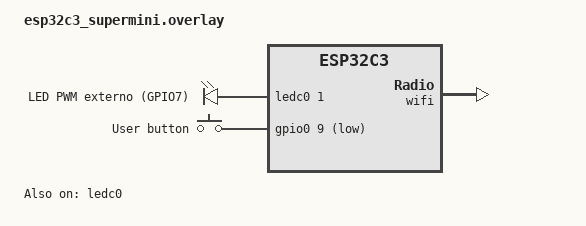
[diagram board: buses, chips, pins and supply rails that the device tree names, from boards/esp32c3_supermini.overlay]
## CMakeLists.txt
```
# SPDX-License-Identifier: Apache-2.0

cmake_minimum_required(VERSION 3.20.0)


# Adiciona o diretório camera_service como módulo extra do Zephyr
set(ZEPHYR_EXTRA_MODULES
    ${CMAKE_CURRENT_SOURCE_DIR}/camera_service
)

find_package(Zephyr REQUIRED HINTS $ENV{ZEPHYR_BASE})
project(emb_base_sample)

# Diretório de headers
zephyr_include_directories(include)

# Arquivos .c
target_sources(app PRIVATE
    src/main.c
    src/sensor_thread.c
    src/control_thread.c
    src/display_thread.c
    src/display.c
    src/radar_core.c
    src/plate_validator.c
)
```

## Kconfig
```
menu "Zephyr"
source "Kconfig.zephyr"

config DISPLAY_ANSI_COLORS
    bool "Ativar cores ANSI no display"
    default y

config DISPLAY_ANSI_CLEAR_ON_UPDATE
    bool "Limpar tela a cada atualização"
    default y

config DISPLAY_ALERT_PERCENT
    int "Percentual de alerta (em % do limite)"
    default 90

config DISPLAY_LIMITE_LEVE
    int "Limite de velocidade para veículos leves"
    default 60


config DISPLAY_LIMITE_PESADO
    int "Limite de velocidade para veículos pesados"
    default 40


config CAMERA_FAKE_FAIL_RATE
    int "Taxa de falha da câmera (%)"
    default 10

config RADAR_CAMERA_FAILURE_RATE_PERCENT
    int "Porcentagem de falha simulada da câmera (%)"
    default 10
    range 0 100

config RADAR_SPEED_LIMIT_LIGHT_KMH
  int "Limit speed for light vehicles (msec)"
  default 60
  range 0 1000

config RADAR_SPEED_LIMIT_HEAVY_KMH
  int "Limit speed for heavy vehicles (msec)"
  default 50
  range 0 1000

config RADAR_SENSOR_DISTANCE_MM
  int "Distances between radar sensors (mm)"
  default 10000
  range 0 100000

endmenu
```

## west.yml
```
# Example T2 west.yml, using manifest imports.
manifest:
  remotes:
    - name: zephyrproject-rtos
      url-base: https://github.com/zephyrproject-rtos
  projects:
    - name: zephyr
      remote: zephyrproject-rtos
      clone-depth: 1
      revision: v4.1.0
      import:
        name-allowlist:
          - cmsis # required by the ARM port
          - hal_nordic # required by the custom_plank board (Nordic based)
path: hello_world
```

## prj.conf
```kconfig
CONFIG_DISPLAY=y
CONFIG_PRINTK=y

CONFIG_TEST_RANDOM_GENERATOR=y
CONFIG_ZBUS=y
CONFIG_ZBUS_MSG_SUBSCRIBER=y
CONFIG_QEMU_ICOUNT=n

CONFIG_GPIO_EMUL=y
CONFIG_GPIO=y
CONFIG_LOG=y

CONFIG_UART_CONSOLE=y

CONFIG_RADAR_SPEED_LIMIT_LIGHT_KMH=80
CONFIG_RADAR_SPEED_LIMIT_HEAVY_KMH=60
CONFIG_RADAR_SENSOR_DISTANCE_MM=3000
```

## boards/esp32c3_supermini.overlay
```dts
#include <zephyr/dt-bindings/gpio/gpio.h>
#include <zephyr/dt-bindings/pwm/pwm.h>
#include <zephyr/dt-bindings/pinctrl/esp32-pinctrl.h>

/* ---- LED PWM em GPIO7 usando LEDC canal 1 ---- */
&pinctrl {
    /* Verifique se este macro existe para o C3: LEDC_CH1_GPIO7 */
    ledc0_gpio7_ch1: ledc0_gpio7_ch1 {
        group1 {
            pinmux = <LEDC_CH1_GPIO7>;
            output-enable;
        };
    };
};

&wifi {
    status = "okay";
};


&ledc0 {
    status = "okay";
    pinctrl-0 = <&ledc0_gpio7_ch1>;
    pinctrl-names = "default";

    #address-cells = <1>;
    #size-cells = <0>;

    channel1: channel@1 {
        reg = <1>;     /* Canal 1 */
        timer = <0>;   /* Timer 0 (0..3) */
        /* inverted;  // opcional */
    };
};

 /{
    aliases {
        led0 = &pwm_led0;
        sw0  = &button0;
    };

    pwmleds {
        compatible = "pwm-leds";
        pwm_led0: pwm_led_0 {
            /* controller, canal, período(ns), flags */
            pwms = <&ledc0 1 1000000 PWM_POLARITY_NORMAL>; /* 1 kHz */
            label = "LED PWM externo (GPIO7)";
        };
    };

    gpio_keys {
        compatible = "gpio-keys";
        button0: button_0 {
            label = "User button";
            gpios = <&gpio0 9 (GPIO_PULL_UP | GPIO_ACTIVE_LOW)>;
        };
    };
};
```

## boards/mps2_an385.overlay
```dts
#include <zephyr/dt-bindings/gpio/gpio.h>

/ {
    chosen {
        zephyr,display = &dummy_dc;
    };

    dummy_dc: dummy_dc {
        compatible = "zephyr,dummy-dc";
        status = "okay";
        width = <80>;
        height = <24>;
    };
};

	aliases {
		button0 = &button0;
		button1 = &button1;
	};

	gpio_sim: gpio_sim {
		compatible = "zephyr,gpio-emul";
		status = "okay";
		gpio-controller;
		#gpio-cells = <2>;
		ngpios = <32>;

		rising-edge;
		falling-edge;
		high-level;
		low-level;
	};

	gpio_keys {
		compatible = "gpio-keys";
		debounce-interval-ms = <20>;

		button0: button_0 {
			gpios = <&gpio_sim 5 (GPIO_PULL_UP | GPIO_ACTIVE_LOW)>;
		};

		button1: button_1 {
			gpios = <&gpio_sim 6 (GPIO_PULL_UP | GPIO_ACTIVE_LOW)>;
		};
	};
};
```

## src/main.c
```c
#include "zephyr/toolchain.h"
#include <stdbool.h>
#include <stdint.h>
#include <zephyr/device.h>
#include <zephyr/drivers/gpio.h>
#include <zephyr/drivers/gpio/gpio_emul.h>
#include <zephyr/drivers/pwm.h>
#include <zephyr/drivers/uart.h>
#include <zephyr/kernel.h>
#include <zephyr/logging/log.h>
#include <zephyr/sys/printk.h>
#include <zephyr/zbus/zbus.h>
#include "camera_service.h"
#include "display.h"
#include "radar_types.h"


LOG_MODULE_REGISTER(semaforo);

K_MSGQ_DEFINE(display_queue, sizeof(struct display_msg), 10, 4);
K_MSGQ_DEFINE(sensor_queue, sizeof(struct data), 10, 4);
K_MSGQ_DEFINE(vehicle_queue, sizeof(struct data), 10, 4);

ZBUS_MSG_SUBSCRIBER_DEFINE(msub_camera_evt);
ZBUS_CHAN_ADD_OBS(chan_camera_evt, msub_camera_evt, 3);

static const struct device *const console_dev = DEVICE_DT_GET(DT_CHOSEN(zephyr_console));
static const struct gpio_dt_spec sensor0 = GPIO_DT_SPEC_GET(DT_ALIAS(button0), gpios);
static const struct gpio_dt_spec sensor1 = GPIO_DT_SPEC_GET(DT_ALIAS(button1), gpios);

extern void sensor_thread(void *, void *, void *);
extern void control_thread(void *, void *, void *);
extern void display_thread(void *, void *, void *);

K_THREAD_DEFINE(control_thread_id, 1024, control_thread, NULL, NULL, NULL, 4, 0, 0);
K_THREAD_DEFINE(sensor_thread_id, 1024, sensor_thread, NULL, NULL, NULL, 4, 0, 0);
K_THREAD_DEFINE(display_thread_id, 1024, display_thread, NULL, NULL, NULL, 4, 0, 0);

static struct gpio_callback sensor0_data;
static struct gpio_callback sensor1_data;



static void sensor0_cb(const struct device *dev, struct gpio_callback *cb, uint32_t pins)
{
	struct data data;

	data.item.from = SENSOR_0;
	data.value.timestamp = k_uptime_get_32();

	k_msgq_put(&sensor_queue, &data, K_NO_WAIT);
}

static void sensor1_cb(const struct device *dev, struct gpio_callback *cb, uint32_t pins)
{
	struct data data;

	data.item.from = SENSOR_1;
	data.value.timestamp = k_uptime_get_32();

	k_msgq_put(&sensor_queue, &data, K_NO_WAIT);
}


int main(void)
{
	int ret;
	uint8_t c;

	LOG_INF("Starting system...");

	if (!gpio_is_ready_dt(&sensor0) || !gpio_is_ready_dt(&sensor1)) {
		LOG_ERR("Error: Sensor GPIO devices are not ready\n");
		return 0;
	}

	ret = gpio_pin_configure_dt(&sensor0, GPIO_INPUT);
	if (ret < 0) {
		LOG_ERR("Error: Failed to configure Sensor 0 pin (err: %d)\n", ret);
		return 0;
	}

	ret = gpio_pin_configure_dt(&sensor1, GPIO_INPUT);
	if (ret < 0) {
		LOG_ERR("Error: Failed to configure Sensor 1 pin (err: %d)\n", ret);
		return 0;
	}

	gpio_init_callback(&sensor0_data, sensor0_cb, BIT(sensor0.pin));
	gpio_add_callback(sensor0.port, &sensor0_data);

	gpio_init_callback(&sensor1_data, sensor1_cb, BIT(sensor1.pin));
	gpio_add_callback(sensor1.port, &sensor1_data);

	ret = gpio_pin_interrupt_configure_dt(&sensor0, GPIO_INT_EDGE_TO_ACTIVE);
	if (ret != 0) {
		LOG_ERR("Error configuring interrupt: %d\n", ret);
		return 0;
	}

	ret = gpio_pin_interrupt_configure_dt(&sensor1, GPIO_INT_EDGE_TO_ACTIVE);
	if (ret != 0) {
		LOG_ERR("Error configuring interrupt: %d\n", ret);
		return 0;
	}

	while (1) {
		if (!uart_poll_in(console_dev, &c)) {
			switch (c) {
			case 49:
				gpio_emul_input_set(sensor0.port, 5, 1);
				gpio_emul_input_set(sensor0.port, 5, 0);
				break;
			case 50:
				gpio_emul_input_set(sensor1.port, 6, 1);
				gpio_emul_input_set(sensor1.port, 6, 0);
				break;
			default:
				break;
			}
		}

		k_msleep(20);
	}

	return 0;
}
```

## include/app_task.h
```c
#pragma once
void app_worker(void *a, void *b, void *c);
```

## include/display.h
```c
#ifndef DISPLAY_H
#define DISPLAY_H

#include "radar_core.h"

void display_update(int velocidade, enum tipo_veiculo_t tipo);

#endif
```

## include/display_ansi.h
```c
#ifndef DISPLAY_ANSI_H
#define DISPLAY_ANSI_H

#ifdef CONFIG_DISPLAY_ANSI_COLORS
    #define ANSI_RED    "\x1b[31m"
    #define ANSI_GREEN  "\x1b[32m"
    #define ANSI_YELLOW "\x1b[33m"
    #define ANSI_RESET  "\x1b[0m"
#else
    #define ANSI_RED    ""
    #define ANSI_GREEN  ""
    #define ANSI_YELLOW ""
    #define ANSI_RESET  ""
#endif

#ifdef CONFIG_DISPLAY_ANSI_CLEAR_ON_UPDATE
    #define ANSI_CLEAR  "\x1b[2J"
    #define ANSI_HOME   "\x1b[H"
#else
    #define ANSI_CLEAR  ""
    #define ANSI_HOME   ""
#endif

#endif
```

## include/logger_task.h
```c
#pragma once
void trace_worker(void *a, void *b, void *c);
```

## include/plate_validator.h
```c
#ifndef PLATE_VALIDATOR_H
#define PLATE_VALIDATOR_H

#include <stdbool.h>

bool plate_is_valid(const char *plate);

#endif
```

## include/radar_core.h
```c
#ifndef RADAR_CORE_H
#define RADAR_CORE_H

enum tipo_veiculo_t {
    VEICULO_LEVE,
    VEICULO_PESADO
};

enum status_t {
    STATUS_OK,
    STATUS_ALERTA,
    STATUS_INFRACAO
};

struct radar_result_t {
    int limite;
    enum status_t status;
};

struct radar_result_t radar_analisar(int velocidade, enum tipo_veiculo_t tipo);

#endif
```

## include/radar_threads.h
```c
#ifndef RADAR_THREADS_H
#define RADAR_THREADS_H

#include <zephyr/kernel.h>
#include "radar_types.h"

extern struct k_msgq display_queue;
extern struct k_msgq sensor_queue;
extern struct k_msgq vehicle_queue;

void display_thread(void *arg1, void *arg2, void *arg3);
void sensor_thread(void *arg1, void *arg2, void *arg3);
void control_thread(void *arg1, void *arg2, void *arg3);

#endif
```

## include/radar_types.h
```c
// include/radar_types.h
#ifndef RADAR_TYPES_H
#define RADAR_TYPES_H

#include <stdint.h>
#include "display.h"  // para enum tipo_veiculo_t

enum STATE {
    IDLE = 0,
    READING,
    DONE
};

enum TYPE {
    LEVE = 0,
    PESADO
};

enum FROM {
    SENSOR_0 = 0,
    SENSOR_1,
    TIMER
};

struct data {
    union item {
        enum FROM from;
        enum TYPE type;
    } item;

    union value {
        uint32_t speed;
        uint32_t timestamp;
    } value;

    int eixos;
};

struct display_msg {
    int velocidade;
    enum tipo_veiculo_t tipo;
};


extern struct k_msgq display_queue;
extern struct k_msgq sensor_queue;
extern struct k_msgq vehicle_queue;

extern bool plate_is_valid(const char *raw);
extern enum STATE radar_state;


#endif
```

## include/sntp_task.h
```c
#pragma once
void ntp_worker(void *a, void *b, void *c);
```

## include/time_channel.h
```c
#pragma once
#include <time.h>
#include <zephyr/zbus/zbus.h>

struct tmsg {
    struct tm when;
};

extern const struct zbus_channel time_channel;
```

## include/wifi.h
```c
#pragma once
#include <stdbool.h>

extern bool net_up;
int net_autostart(void);
```

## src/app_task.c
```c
#include <inttypes.h>
#include <zephyr/kernel.h>
#include <zephyr/logging/log.h>
#include <zephyr/zbus/zbus.h>
#include <zephyr/sys/timeutil.h>
#include "time_channel.h"
#include "app_task.h"

LOG_MODULE_REGISTER(app_run, LOG_LEVEL_INF);

ZBUS_SUBSCRIBER_DEFINE(app_obs, 4);

void app_worker(void *a, void *b, void *c)
{
    ARG_UNUSED(a);
    ARG_UNUSED(b);
    ARG_UNUSED(c);

    const struct zbus_channel *ch;
    struct tmsg m;
    static struct tm prev = {0};
    bool have_prev = false;

    char fmt[64], out[32];
    snprintf(fmt, sizeof(fmt), "%%a %%Y-%%m-%%d %%H:%%M:%%S %%Z%+d", CONFIG_LOCAL_TIME);

    for (;;) {
        if (zbus_sub_wait(&app_obs, &ch, K_FOREVER) != 0) continue;
        if (zbus_chan_read(ch, &m, K_FOREVER) != 0) continue;

        if (!have_prev) { prev = m.when; have_prev = true; }

        int64_t ta = timeutil_timegm64(&prev);
        int64_t tb = timeutil_timegm64(&m.when);
        int64_t dt = tb - ta;

        strftime(out, sizeof(out), fmt, &m.when);
        LOG_INF("[APP] dt=%" PRId64 "s now=%s", dt, out);

        prev = m.when;
    }
}
```
